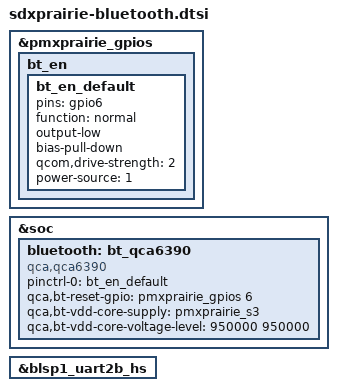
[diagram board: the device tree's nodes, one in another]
/* Copyright (c) 2019, The Linux Foundation. All rights reserved.
 *
 * This program is free software; you can redistribute it and/or modify
 * it under the terms of the GNU General Public License version 2 and
 * only version 2 as published by the Free Software Foundation.
 *
 * This program is distributed in the hope that it will be useful,
 * but WITHOUT ANY WARRANTY; without even the implied warranty of
 * MERCHANTABILITY or FITNESS FOR A PARTICULAR PURPOSE.  See the
 * GNU General Public License for more details.
 */

&pmxprairie_gpios {
	bt_en {
		bt_en_default: bt_en_default {
			pins = "gpio6";
			function = "normal";
			output-low;
			bias-pull-down;
			qcom,drive-strength = <2>;
			power-source = <1>;
		};
	};
};

&soc {
	bluetooth: bt_qca6390 {
		compatible = "qca,qca6390";
		pinctrl-names = "default";
		pinctrl-0 = <&bt_en_default>;
		qca,bt-reset-gpio = <&pmxprairie_gpios 6 0>;
		qca,bt-vdd-core-supply = <&pmxprairie_s3>; /* VDD_PMU_AON_I */
		qca,bt-vdd-core-voltage-level = <950000 950000>;
	};
};

&blsp1_uart2b_hs {
	status = "okay";
};
